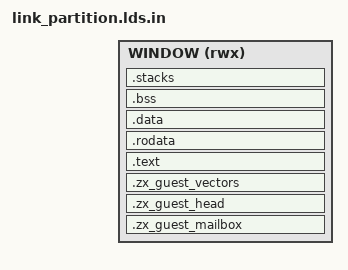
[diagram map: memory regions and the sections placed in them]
/***************************************************************************
 * Copyright (c) 2026 Eclipse ThreadX contributors
 *
 * This program and the accompanying materials are made available under the
 * terms of the MIT License which is available at
 * https://opensource.org/licenses/MIT.
 *
 * AI Disclosure: This file was largely AI-generated by Claude Code (Opus 5).
 * The AI-generated portions may be considered public domain (CC0-1.0)
 * and not subject to the project's licence. The human contributor has
 * reviewed and verified that the code is correct.
 *
 * SPDX-License-Identifier: MIT and CC0-1.0
 **************************************************************************/

/* Link map for a ThreadX guest inside a ZoneX partition, Armv8-R AEM FVP.
 *
 * A TEMPLATE, configured once per partition.
 *
 * The window base and size below are substituted by CMake, and that is the
 * answer to a question this repository asked deliberately: adding a second
 * partition was meant to be a data change plus one more .incbin, and it was
 * not -- it was going to be a second copy of a two-hundred-line build file
 * and a second copy of this script, differing in one number each.
 *
 * Two copies of an argument stay true until the day they do not, and the day
 * they do not is a guest linked for a window it is not loaded into: it
 * STARTS, because the entry branch is PC-relative, and faults at its first
 * literal pool load at an address that looks entirely reasonable.  So the
 * script is one file and the number is data.  The image still declares what
 * it was built for in its own header, and the hypervisor still refuses a
 * mismatch at boot -- the template removes a way to create one, not the
 * check that catches it.
 *
 * WHAT MAKES THIS DIFFERENT FROM THE PORT'S OWN link.lds
 *
 * The guest does not own the machine.  It owns ONE CONTIGUOUS WINDOW, whose
 * base and size are a property of the hypervisor's manifest rather than of
 * the board, and everything the guest has -- code, rodata, data, bss, every
 * per-mode stack -- has to fit inside it.  Three consequences:
 *
 *   * The window base is declared HERE and in the hypervisor's own linker
 *     script, and the two must agree.  They are checked against each other
 *     at run time: the hypervisor's loader compares the manifest's window
 *     against the image it was handed, and the image asserts its own base
 *     below.  A guest linked for the wrong address is otherwise a guest
 *     that runs until its first literal pool load.
 *
 *   * The layout is granule-aligned at three points rather than one,
 *     because the guest programs its OWN stage-1 MPU over three regions
 *     inside the window -- the mailbox, the code, and everything writable.
 *     PMSAv8-R has no region priority at either stage, so those three must
 *     not overlap, which means each boundary is a 64-byte boundary.
 *
 *   * KEEPING THE WINDOW CONTIGUOUS IS NOT OPTIONAL, and the reason is
 *     objcopy rather than the MPU.  "objcopy -O binary" spans any gap
 *     between loaded sections and emits the gap as padding, so a guest
 *     split across two far-apart memory areas produces a blob the size of
 *     the distance between them.  On the S32Z280 that distance is 1.2 GB.
 *     One window, one blob, no gap.
 *
 * WHY THE FIRST TWO SECTIONS ARE AT FIXED OFFSETS
 *
 * The hypervisor computes both as window_base plus a compile-time constant
 * from examples/common/zx_guest_abi.h, because it has a raw blob and no
 * symbol table to look anything up in:
 *
 *     +0x00   the readback mailbox, THREE granules
 *     +0xC0   one branch to the kernel's reset symbol -- the ERET target
 *
 * The ASSERTs at the end are what make those constants true rather than
 * hoped for.
 *
 * A NOTE ON ALIGN, because the two spellings are not equivalent
 *
 * Every ALIGN below is written AFTER the colon, which is the section's
 * ALIGNMENT.  Written before the colon it is the section's ADDRESS,
 * evaluated from a location counter that starts at zero, and it silently
 * overrides "> WINDOW".  That is harmless on a target whose memory starts at
 * zero and catastrophic on one whose does not -- which is precisely what
 * makes it a trap worth stating in every script in this repository rather
 * than in one of them.
 */

ENTRY(_start)

/* THE WINDOW.  These two numbers are the contract with the hypervisor's own
   linker script and manifest.  Changing either means changing both.

   256 KB is not a measurement, it is headroom: the guest below links to
   roughly a tenth of it, and a window sized to what the image happens to
   need today would fail the ASSERT the first time a demo grew a thread.
   The stage-2 region costs the same whatever its size.

   BOTH ARE SUBSTITUTED BY CMAKE, from the values the hypervisor's own
   linker script declares, so the two cannot disagree by being edited apart.
   Every partition on this board gets the same size and a different base. */

__zx_guest_window_base = @ZX_GUEST_WINDOW_BASE@;
__zx_guest_window_size = @ZX_GUEST_WINDOW_SIZE@;

/* Per-mode stacks.  Every AArch32 mode needs one and the port's el1_entry
   sets all six; a mode whose stack symbol was missing would fail the link,
   which is the good outcome.  These are smaller than the standalone board's
   because a partition's window is a budget rather than a whole DRAM.  */

__hyp_stack_size__ = 0x0100;    /* unused at EL1, kept so the port links    */
__svc_stack_size__ = 0x0800;
__irq_stack_size__ = 0x0400;
__fiq_stack_size__ = 0x0200;
__abt_stack_size__ = 0x0200;
__und_stack_size__ = 0x0200;
__sys_stack_size__ = 0x0400;

MEMORY
{
    WINDOW (rwx) : ORIGIN = @ZX_GUEST_WINDOW_BASE@, LENGTH = @ZX_GUEST_WINDOW_SIZE@
}

SECTIONS
{
    /* ---------------------------------------------------------------- */
    /*  +0x00  the mailbox, three granules.                            */
    /*                                                                  */
    /*  LOADED, not NOLOAD, and that is what fixes the whole layout.    */
    /*  objcopy -O binary emits only sections with contents, so a       */
    /*  NOLOAD section at the front would be skipped and the blob's     */
    /*  byte zero would be the SECOND section -- the image shifted by a */
    /*  granule, copied to the window base, and executed from the wrong */
    /*  place.  It is also outside .bss on purpose: the port's boot     */
    /*  path zeroes .bss, and the hypervisor writes the mailbox BEFORE  */
    /*  the ERET.                                                      */
    /* ---------------------------------------------------------------- */

    .zx_guest_mailbox : ALIGN(64)
    {
        __zx_guest_mailbox_start = .;
        KEEP(*(.zx_guest_mailbox))
        . = ALIGN(64);
        __zx_guest_mailbox_end = .;
    } > WINDOW

    /* ---------------------------------------------------------------- */
    /*  +0xC0  the entry branch, then everything executable.           */
    /*                                                                  */
    /*  One stage-1 region covers all of it, read-only and executable.  */
    /*  Read-only at EL1 while stage 2 permits the write is the case    */
    /*  where the two stages disagree, and it is what the deliberate    */
    /*  stage-1 fault build provokes.                                   */
    /* ---------------------------------------------------------------- */

    .zx_guest_head : ALIGN(64)
    {
        __zx_guest_code_start = .;
        KEEP(*(.zx_guest_head))
    } > WINDOW

    .zx_guest_vectors : ALIGN(32)
    {
        KEEP(*(.zx_guest_vectors))
    } > WINDOW

    .text :
    {
        KEEP(*(.vectors_el2))
        KEEP(*(.vectors_el1))
        *(.text*)
        *(.glue_7)
        *(.glue_7t)
    } > WINDOW

    .rodata :
    {
        . = ALIGN(4);
        *(.rodata*)
        . = ALIGN(4);
    } > WINDOW

    /* ---------------------------------------------------------------- */
    /*  Everything writable, from a granule boundary.                   */
    /*                                                                  */
    /*  The alignment belongs on the output section itself.  An         */
    /*  assignment between sections does not advance a MEMORY region's  */
    /*  allocation pointer, and ". = ALIGN(64);" at the end of .rodata  */
    /*  does not extend that section when no data follows it -- in both */
    /*  cases .data keeps its unaligned address while the symbol        */
    /*  reports the aligned one, and the first bytes of .data fall      */
    /*  inside the read-only code region.  The Cortex-R52 port's MPU    */
    /*  caught exactly that, and the variable it broke was the flag the */
    /*  abort handler consults -- so the fault turned itself fatal.     */
    /* ---------------------------------------------------------------- */

    .data : ALIGN(64)
    {
        __zx_guest_code_end = .;
        __zx_guest_data_start = .;
        __data_start__ = .;
        *(.data*)
        . = ALIGN(4);
    } > WINDOW

    .bss (NOLOAD) :
    {
        . = ALIGN(4);
        __bss_start__ = .;
        *(.bss*)
        *(COMMON)
        . = ALIGN(4);
        __bss_end__ = .;
    } > WINDOW

    .stacks (NOLOAD) :
    {
        . = ALIGN(8);
        . = . + __hyp_stack_size__;
        __hyp_stack_top = .;

        . = ALIGN(8);
        . = . + __svc_stack_size__;
        __svc_stack_top = .;

        . = ALIGN(8);
        . = . + __irq_stack_size__;
        __irq_stack_top = .;

        . = ALIGN(8);
        . = . + __fiq_stack_size__;
        __fiq_stack_top = .;

        . = ALIGN(8);
        . = . + __abt_stack_size__;
        __abt_stack_top = .;

        . = ALIGN(8);
        . = . + __und_stack_size__;
        __und_stack_top = .;

        . = ALIGN(8);
        . = . + __sys_stack_size__;
        __sys_stack_top = .;
    } > WINDOW

    . = ALIGN(8);
    _end = .;
    PROVIDE(end = .);

    /* The writable stage-1 region runs to the end of the window, not to
       _end.  _tx_initialize_low_level publishes _end as the first free
       address and tx_application_define is free to carve from it; this
       guest does not, but a region that stopped at _end would make the
       next guest that does fault on memory the manifest granted it.  */

    __zx_guest_window_end = __zx_guest_window_base + __zx_guest_window_size;
    __zx_guest_data_end   = __zx_guest_window_end;
    __data_end__          = __zx_guest_window_end;
    __code_start__        = __zx_guest_code_start;
    __code_end__          = __zx_guest_code_end;

    /* ---------------------------------------------------------------- */
    /*  The geometry the hypervisor computes from constants.             */
    /*                                                                  */
    /*  Each of these would otherwise be a run-time mystery.  An         */
    /*  under-aligned base does not fault -- its low bits land on SH,    */
    /*  AP and XN and silently change what a region grants -- and an     */
    /*  entry point four bytes out of place is invisible in a manifest   */
    /*  and costs a hardware session to find.                            */
    /* ---------------------------------------------------------------- */

    ASSERT(__zx_guest_mailbox_start == __zx_guest_window_base,
           "the mailbox is not at the base of the partition window")
    /* THREE granules, and the number is ZX_GD_WINDOW_SIZE in
       examples/common/zx_guest_abi.h.  A linker script cannot include a
       C header, so the constant is restated here and asserted -- which
       is the point: a mailbox that grew past its slot fails the LINK
       rather than moving an entry point the hypervisor computes as a
       compile-time constant.  It HAS grown, twice, and both times this
       assert is what said so before anything ran.  */
    ASSERT((__zx_guest_mailbox_end - __zx_guest_mailbox_start) == 192,
           "the mailbox is not exactly three granules")
    /* ZX_GUEST_IMAGE_OFF_ENTRY.  Restated for the same reason as the
       mailbox size above, and it moves with it: three granules of mailbox
       put the entry branch at 0xC0.  A guest whose branch is four bytes
       out of place is invisible in a manifest and costs a hardware
       session to find.  */
    ASSERT(__zx_guest_code_start == (__zx_guest_window_base + 0xC0),
           "the entry branch is not at the offset the hypervisor ERETs to")
    ASSERT(_start >= __zx_guest_code_start,
           "the kernel's reset symbol is outside the guest's code region")
    ASSERT(_start < __zx_guest_code_end,
           "the kernel's reset symbol is outside the guest's code region")

    ASSERT((__zx_guest_code_start & 63) == 0,
           "the guest's code region base is not 64-byte aligned")
    ASSERT((__zx_guest_code_end & 63) == 0,
           "the guest's code region does not end on a granule boundary")
    ASSERT((__zx_guest_data_start & 63) == 0,
           "the guest's writable region base is not 64-byte aligned")

    /* The mailbox must NOT be inside the range the port's boot path zeroes,
       or the hypervisor's handover is wiped by its own recipient before any
       C runs -- a guest that reported nothing and a guest that never
       started would then be indistinguishable.  */

    ASSERT(__zx_guest_mailbox_end <= __bss_start__,
           "the mailbox overlaps .bss, which the boot path zeroes")

    /* And the whole image has to fit the window it was linked for.  The
       hypervisor checks this too, from the manifest, and it is asserted
       here as well because the two checks catch different mistakes: the
       link-time one catches a guest that outgrew its window, the run-time
       one catches a manifest that disagrees with the guest.  */

    ASSERT(_end <= __zx_guest_window_end,
           "the guest image does not fit its partition window")
}
